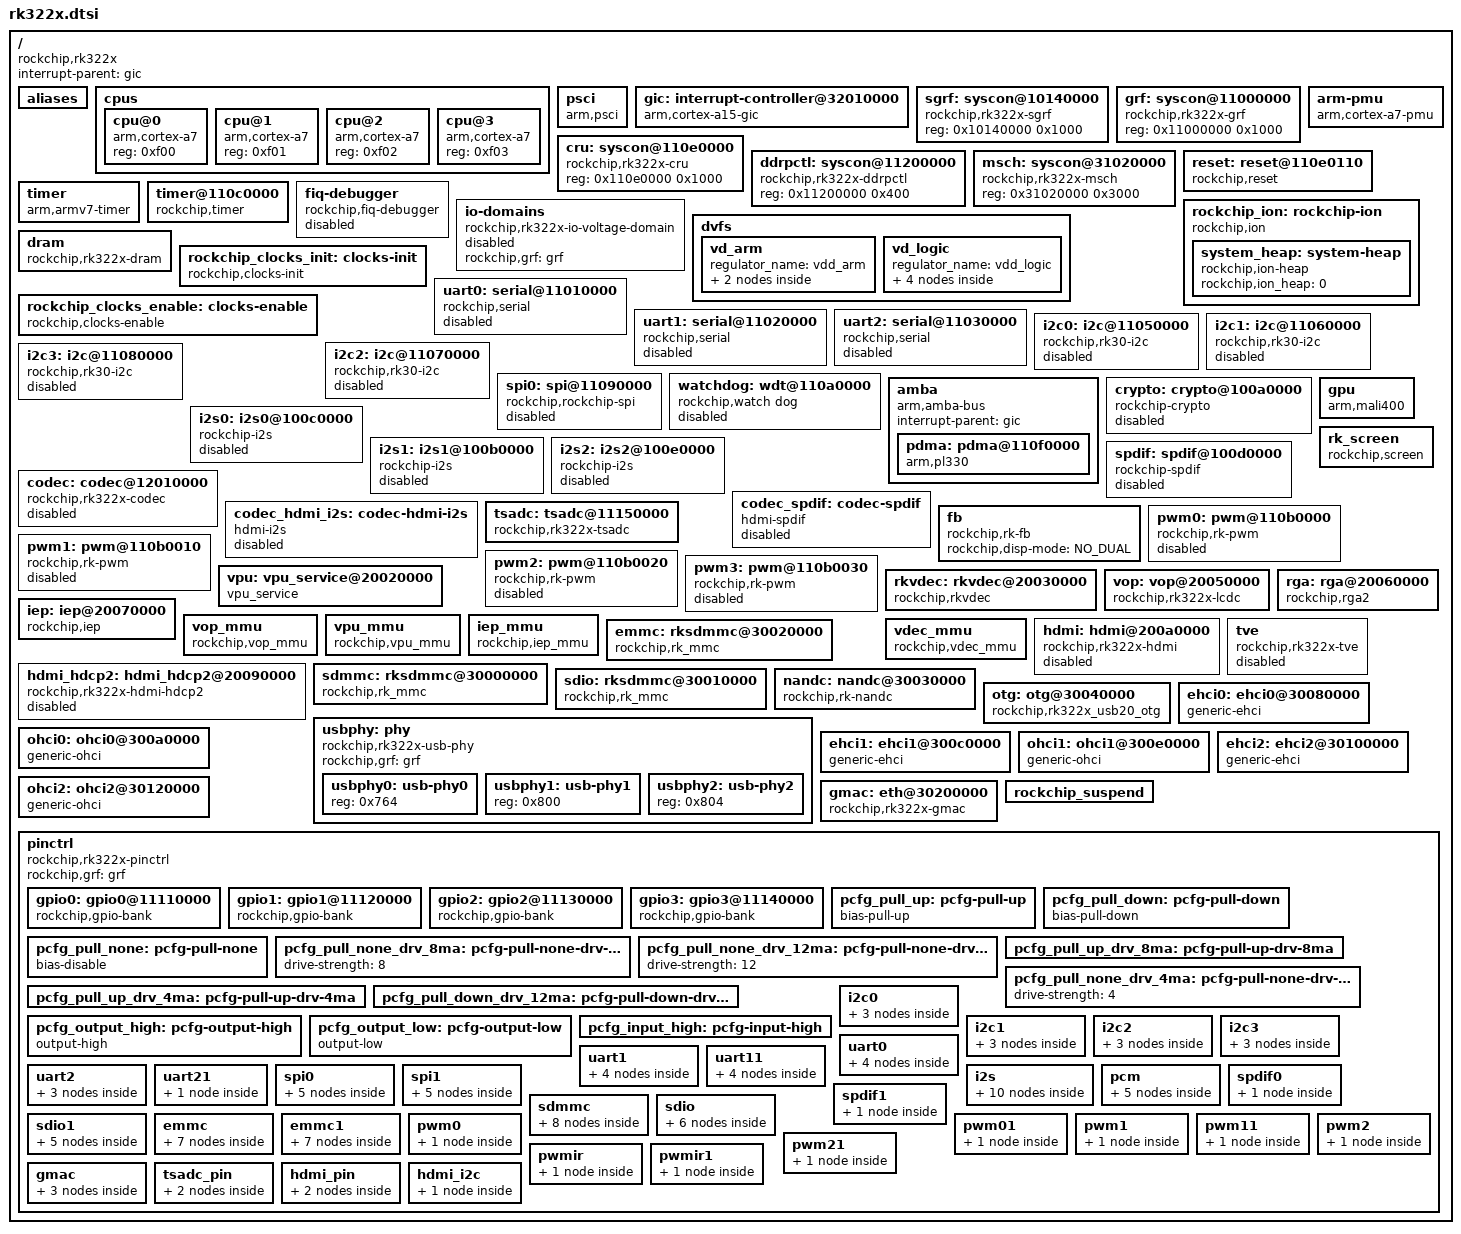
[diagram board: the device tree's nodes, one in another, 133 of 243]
#include <dt-bindings/interrupt-controller/arm-gic.h>
#include <dt-bindings/rkfb/rk_fb.h>

#include "skeleton.dtsi"
#include "rk322x-clocks.dtsi"

#include <dt-bindings/pinctrl/rockchip.h>
#include <dt-bindings/gpio/gpio.h>
#include <dt-bindings/clock/rk_system_status.h>
#include <rk322x_dram_default_timing.dtsi>
#include <dt-bindings/suspend/rockchip-pm.h>

/ {
	compatible = "rockchip,rk322x";
	interrupt-parent = <&gic>;

	aliases {
		serial0 = &uart0;
		serial1 = &uart1;
		serial2 = &uart2;
		i2c0 = &i2c0;
		i2c1 = &i2c1;
		i2c2 = &i2c2;
		i2c3 = &i2c3;
		lcdc0 = &vop;
		spi0 = &spi0;
	};

	cpus {
		#address-cells = <1>;
		#size-cells = <0>;

		cpu@0 {
			device_type = "cpu";
			compatible = "arm,cortex-a7";
			reg = <0xf00>;
		};
		cpu@1 {
			device_type = "cpu";
			compatible = "arm,cortex-a7";
			reg = <0xf01>;
		};
		cpu@2 {
			device_type = "cpu";
			compatible = "arm,cortex-a7";
			reg = <0xf02>;
		};
		cpu@3 {
			device_type = "cpu";
			compatible = "arm,cortex-a7";
			reg = <0xf03>;
		};
	};

	psci {
		compatible      = "arm,psci";
		method          = "smc";
		cpu_suspend     = <0x84000001>;
		cpu_off         = <0x84000002>;
		cpu_on          = <0x84000003>;
	};

	gic: interrupt-controller@32010000 {
		compatible = "arm,cortex-a15-gic";
		interrupt-controller;
		#interrupt-cells = <3>;
		#address-cells = <0>;
		reg = <0x32011000 0x1000>,
		      <0x32012000 0x1000>;
	};

	sgrf: syscon@10140000 {
		compatible = "rockchip,rk322x-sgrf", "rockchip,sgrf", "syscon";
		reg = <0x10140000 0x1000>;
	};

	grf: syscon@11000000 {
		compatible = "rockchip,rk322x-grf", "rockchip,grf", "syscon";
		reg = <0x11000000 0x1000>;
	};

	cru: syscon@110e0000 {
		compatible = "rockchip,rk322x-cru", "rockchip,cru", "syscon";
		reg = <0x110e0000 0x1000>;
	};

	ddrpctl: syscon@11200000 {
		compatible = "rockchip,rk322x-ddrpctl", "syscon";
		reg = <0x11200000 0x400>;
	};

	msch: syscon@31020000 {
		compatible = "rockchip,rk322x-msch", "rockchip,msch", "syscon";
		reg = <0x31020000 0x3000>;
	};

	arm-pmu {
		compatible = "arm,cortex-a7-pmu";
		interrupts = <GIC_SPI 76 IRQ_TYPE_LEVEL_HIGH>,
			     <GIC_SPI 77 IRQ_TYPE_LEVEL_HIGH>,
			     <GIC_SPI 78 IRQ_TYPE_LEVEL_HIGH>,
			     <GIC_SPI 79 IRQ_TYPE_LEVEL_HIGH>;
	};

	reset: reset@110e0110{
		compatible = "rockchip,reset";
		reg = <0x110e0110 0x20>;
		rockchip,reset-flag = <ROCKCHIP_RESET_HIWORD_MASK>;
		#reset-cells = <1>;
	};

	timer {
		compatible = "arm,armv7-timer";
		interrupts = <GIC_PPI 13
			      (GIC_CPU_MASK_SIMPLE(4) | IRQ_TYPE_LEVEL_HIGH)>,
			     <GIC_PPI 14
			      (GIC_CPU_MASK_SIMPLE(4) | IRQ_TYPE_LEVEL_HIGH)>;
		clock-frequency = <24000000>;
	};

	timer@110c0000 {
		compatible = "rockchip,timer";
		reg = <0x110c0000 0x20>;
		interrupts = <GIC_SPI 43 IRQ_TYPE_LEVEL_HIGH>;
		rockchip,broadcast = <1>;
	};

	fiq-debugger {
		compatible = "rockchip,fiq-debugger";
		rockchip,serial-id = <2>;
		rockchip,signal-irq = <159>;
		rockchip,wake-irq = <0>;
		rockchip,irq-mode-enable = <0>;  /* If enable uart uses irq instead of fiq */
		rockchip,baudrate = <1500000>;  /* Only 115200 and 1500000 */
		pinctrl-names = "default";
		pinctrl-0 = <&uart21_xfer>;
		status = "disabled";
	};

	io-domains {
		compatible = "rockchip,rk322x-io-voltage-domain";
		rockchip,grf = <&grf>;
		status = "disabled";
	};

	dvfs {
		vd_arm: vd_arm {
			regulator_name = "vdd_arm";
			pd_core {
				clk_core_dvfs_table: clk_core {
					operating-points = <
						/* KHz    uV */
						312000 1200000
						504000 1200000
						816000 1200000
						1008000 1200000
						>;
					temp-limit-enable = <1>;
					target-temp = <95>;
					min_temp_limit = <600000>;
					normal-temp-limit = <
					/*delta-temp    delta-freq*/
						3	96000
						6	144000
						9	192000
						15	384000
						>;
					performance-temp-limit = <
						/*temp    freq*/
						110     816000
						>;
					status = "okay";
					regu-mode-table = <
						/*freq     mode*/
						1008000    4
						0          3
					>;
					regu-mode-en = <0>;
					lkg_adjust_volt_en = <1>;
					channel = <0>;
					tsadc-ch = <0>;
					def_table_lkg = <4>;
					min_adjust_freq = <1008000>;
					lkg_adjust_volt_table = <
						/*lkg(mA)  volt(uV)*/
						10	   50000
						20	   100000
						60         150000
						>;
				};
			};
		};

		vd_logic: vd_logic {
			regulator_name = "vdd_logic";
			pd_ddr {
				clk_ddr_dvfs_table: clk_ddr {
					operating-points = <
						/* KHz    uV */
						200000 1200000
						300000 1200000
						400000 1200000
						>;
					lkg_adjust_volt_en = <1>;
					channel = <2>;
					def_table_lkg = <5>;
					min_adjust_freq = <300000>;
					lkg_adjust_volt_table = <
						/*lkg(mA)  volt(uV)*/
						7	   50000
						60         100000
						>;
					status = "disabled";
				};
			};

			pd_gpu {
				clk_gpu_dvfs_table: clk_gpu {
					operating-points = <
						/* KHz    uV */
						200000 1200000
						300000 1200000
						400000 1200000
						>;
					channel = <2>;
					status = "okay";
					regu-mode-table = <
						/*freq     mode*/
						200000     4
						0          3
					>;
					regu-mode-en = <0>;
				};
			};
		};
	};

	rockchip_ion: rockchip-ion {
		compatible = "rockchip,ion";
		#address-cells = <1>;
		#size-cells = <0>;

		system_heap: system-heap {
			compatible = "rockchip,ion-heap";
			rockchip,ion_heap = <0>;
		};
	};

	dram: dram {
		compatible = "rockchip,rk322x-dram";
		status = "okay";
		dram_freq = <786000000>;
		rockchip,dram_timing = <&dram_timing>;
	};

	rockchip_clocks_init: clocks-init{
		compatible = "rockchip,clocks-init";
		rockchip,clocks-init-parent =
			<&clk_i2s0_pll &clk_gpll>, <&clk_i2s1_pll &clk_gpll>,
			<&clk_i2s2_pll &clk_gpll>, <&clk_spdif_pll &clk_gpll>,
			<&clk_gpu &clk_cpll>, <&dclk_vop0 &hdmi_phy_clk>,
			<&aclk_bus &clk_gpll>, <&aclk_peri &clk_gpll>,
			<&clk_sdmmc0 &clk_cpll>, <&clk_emmc &clk_cpll>,
			<&clk_sdio &clk_cpll>, <&aclk_vpu &clk_cpll>,
			<&hdmi_phy_clk &hdmiphy_out>, <&usb480m &usb480m_phy>,
			<&aclk_rkvdec &clk_cpll>;
		rockchip,clocks-init-rate =
			<&clk_gpll 1200000000>, <&clk_core 700000000>,
			<&clk_cpll 500000000>, <&aclk_bus 150000000>,
			<&hclk_bus 150000000>, <&pclk_bus 75000000>,
			<&aclk_peri 150000000>, <&hclk_peri 150000000>,
			<&pclk_peri 75000000>, <&clk_mac 125000000>,
			<&aclk_iep 250000000>, <&hclk_vio 125000000>,
			<&aclk_rga 250000000>, <&clk_gpu 250000000>,
			<&aclk_vpu 25000000>, <&clk_vdec_core 250000000>,
			<&clk_vdec_cabac 250000000>, <&aclk_rkvdec 16000000>,
			<&aclk_vop 400000000>;
/*
		rockchip,clocks-uboot-has-init =
			<&aclk_vio0>;
*/
	};

	rockchip_clocks_enable: clocks-enable {
		compatible = "rockchip,clocks-enable";
		clocks =
			/*PLL*/
			<&clk_apll>,
			<&clk_dpll>,
			<&clk_gpll>,
			<&clk_cpll>,

			/*PD_CORE*/
			<&clk_core>,
			<&pclk_dbg>,
			<&aclk_core>,
			<&clk_gates4 2>,

			/*PD_BUS*/
			<&clk_gates6 3>,/*pclk_bus_pre*/
			<&clk_gates7 1>,/*clk4x_ddrphy*/
			<&clk_gates8 5>,/*clk_ddrupctl*/
			<&clk_gates8 0>,/*aclk_intmem*/
			<&clk_gates8 1>,/*clk_intmem_mbist*/
			<&clk_gates8 2>,/*aclk_dmac_bus*/
			<&clk_gates10 1>,/*g_aclk_bus*/
			<&clk_gates8 3>,/*hclk_rom*/
			<&clk_gates8 4>,/*pclk_ddrupctl*/
			<&clk_gates8 6>,/*pclk_ddrmon*/
			<&clk_gates9 4>,/*pclk_timer0*/
			<&clk_gates9 5>,/*pclk_stimer*/
			<&clk_gates9 8>,/*pclk_gpio0*/
			<&clk_gates10 0>,/*pclk_grf*/
			<&clk_gates10 4>,/*pclk_cru*/
			<&clk_gates10 6>,/*pclk_sgrf*/
			<&clk_gates10 3>,/*pclk_ddrphy*/
			<&clk_gates10 9>,/*pclk_phy_noc*/
			<&clk_gates10 2>,/*pclk_mschniu*/

			/*PD_PERI*/
			<&clk_gates12 0>,/*aclk_peri_noc*/
			<&clk_gates12 1>,/*hclk_peri_noc*/
			<&clk_gates12 2>,/*pclk_peri_noc*/

			/*PD_VIO*/
			<&clk_gates13 7>,/*hclk_vio_ahb_arbi*/
			<&clk_gates14 7>,/*hclk_vio_h2p*/

			<&clk_gates6 5>, /* g_clk_timer0 */
			<&clk_gates6 6>, /* g_clk_timer1 */

			/*PD_VIDEO*/
			<&clk_gates15 4>,/*g_aclk_vpu_noc*/
			<&clk_gates15 6>,/*g_aclk_rkvdec_noc*/
			<&clk_gates15 5>,/*g_hclk_vpu_noc*/
			<&clk_gates15 7>,/*g_hclk_rkvdec_noc*/

			<&clk_gates13 11>,/*g_aclk_rga_noc*/
			
			<&clk_gates7 15>, /* g_aclk_gpu_noc */

			<&clk_gates13 9>,/*g_aclk_iep_noc*/
			<&clk_gates13 12>,/*g_aclk_vop_noc*/
			<&clk_gates13 10>,/*g_aclk_hdcp_noc*/
			<&clk_gates13 8>,/*g_hclk_vio_noc*/
			<&clk_gates13 13>,/*g_hclk_vop_noc*/

			<&clk_gates1 3>;/*clk_jtag*/
	};

	uart0: serial@11010000 {
		compatible = "rockchip,serial";
		reg = <0x11010000 0x100>;
		interrupts = <GIC_SPI 55 IRQ_TYPE_LEVEL_HIGH>;
		clock-frequency = <24000000>;
		clocks = <&clk_uart0>, <&clk_gates9 12>;
		clock-names = "sclk_uart", "pclk_uart";
		reg-shift = <2>;
		reg-io-width = <4>;
		dmas = <&pdma 2>, <&pdma 3>;
		#dma-cells = <2>;
		pinctrl-names = "default";
		pinctrl-0 = <&uart0_xfer &uart0_cts &uart0_rts>;
		status = "disabled";
	};

	uart1: serial@11020000 {
		compatible = "rockchip,serial";
		reg = <0x11020000 0x100>;
		interrupts = <GIC_SPI 56 IRQ_TYPE_LEVEL_HIGH>;
		clock-frequency = <24000000>;
		clocks = <&clk_uart1>, <&clk_gates9 13>;
		clock-names = "sclk_uart", "pclk_uart";
		reg-shift = <2>;
		reg-io-width = <4>;
		dmas = <&pdma 4>, <&pdma 5>;
		#dma-cells = <2>;
		pinctrl-names = "default";
		pinctrl-0 = <&uart11_xfer &uart11_cts &uart11_rts>;
		status = "disabled";
	};

	uart2: serial@11030000 {
		compatible = "rockchip,serial";
		reg = <0x11030000 0x100>;
		interrupts = <GIC_SPI 57 IRQ_TYPE_LEVEL_HIGH>;
		clock-frequency = <24000000>;
		clocks = <&clk_uart2>, <&clk_gates9 14>;
		clock-names = "sclk_uart", "pclk_uart";
		reg-shift = <2>;
		reg-io-width = <4>;
		dmas = <&pdma 6>, <&pdma 7>;
		#dma-cells = <2>;
		pinctrl-names = "default";
		pinctrl-0 = <&uart21_xfer>;
		status = "disabled";
	};

	i2c0: i2c@11050000 {
		compatible = "rockchip,rk30-i2c";
		reg = <0x11050000 0x1000>;
		interrupts = <GIC_SPI 36 IRQ_TYPE_LEVEL_HIGH>;
		#address-cells = <1>;
		#size-cells = <0>;
		pinctrl-names = "default", "gpio", "sleep";
		pinctrl-0 = <&i2c0_xfer>;
		pinctrl-1 = <&i2c0_gpio>;
		pinctrl-2 = <&i2c0_sleep>;
		gpios = <&gpio0 GPIO_A1 GPIO_ACTIVE_LOW>,
			<&gpio0 GPIO_A0 GPIO_ACTIVE_LOW>;
		clocks = <&clk_gates8 15>;
		rockchip,check-idle = <1>;
		status = "disabled";
	};

	i2c1: i2c@11060000 {
		compatible = "rockchip,rk30-i2c";
		reg = <0x11060000 0x1000>;
		interrupts = <GIC_SPI 37 IRQ_TYPE_LEVEL_HIGH>;
		#address-cells = <1>;
		#size-cells = <0>;
		pinctrl-names = "default", "gpio", "sleep";
		pinctrl-0 = <&i2c1_xfer>;
		pinctrl-1 = <&i2c1_gpio>;
		pinctrl-2 = <&i2c1_sleep>;
		gpios = <&gpio0 GPIO_A3 GPIO_ACTIVE_LOW>,
			<&gpio0 GPIO_A2 GPIO_ACTIVE_LOW>;
		clocks = <&clk_gates9 0>;
		rockchip,check-idle = <1>;
		status = "disabled";
	};

	i2c2: i2c@11070000 {
		compatible = "rockchip,rk30-i2c";
		reg = <0x11070000 0x1000>;
		interrupts = <GIC_SPI 38 IRQ_TYPE_LEVEL_HIGH>;
		#address-cells = <1>;
		#size-cells = <0>;
		pinctrl-names = "default", "gpio", "sleep";
		pinctrl-0 = <&i2c2_xfer>;
		pinctrl-1 = <&i2c2_gpio>;
		pinctrl-2 = <&i2c2_sleep>;
		gpios = <&gpio2 GPIO_C4 GPIO_ACTIVE_LOW>,
			<&gpio2 GPIO_C5 GPIO_ACTIVE_LOW>;
		clocks = <&clk_gates9 1>;
		rockchip,check-idle = <1>;
		status = "disabled";
	};

	i2c3: i2c@11080000 {
		compatible = "rockchip,rk30-i2c";
		reg = <0x11080000 0x1000>;
		interrupts = <GIC_SPI 39 IRQ_TYPE_LEVEL_HIGH>;
		#address-cells = <1>;
		#size-cells = <0>;
		pinctrl-names = "default", "gpio", "sleep";
		pinctrl-0 = <&i2c3_xfer>;
		pinctrl-1 = <&i2c3_gpio>;
		pinctrl-2 = <&i2c3_sleep>;
		gpios = <&gpio0 GPIO_A7 GPIO_ACTIVE_LOW>,
			<&gpio0 GPIO_A6 GPIO_ACTIVE_LOW>;
		clocks = <&clk_gates9 2>;
		rockchip,check-idle = <1>;
		status = "disabled";
	};

	spi0: spi@11090000 {
		compatible = "rockchip,rockchip-spi";
		reg = <0x11090000 0x1000>;
		interrupts = <GIC_SPI 49 IRQ_TYPE_LEVEL_HIGH>;
		#address-cells = <1>;
		#size-cells = <0>;
		pinctrl-names = "default";
		pinctrl-0 = <&spi0_clk &spi0_tx &spi0_rx &spi0_cs0 &spi0_cs1>;
		rockchip,spi-src-clk = <0>;
		num-cs = <2>;
		clocks =<&clk_gates2 9>, <&clk_gates9 6>;
		clock-names = "spi", "pclk_spi0";
		//dmas = <&pdma 8>, <&pdma 9>;
		//#dma-cells = <2>;
		//dma-names = "!tx", "rx";
		status = "disabled";
	};

	watchdog: wdt@110a0000 {
		compatible = "rockchip,watch dog";
		reg = <0x110a0000 0x100>;
		clocks = <&clk_gates6 3>;  /* pclk_bus_pre */
		clock-names = "pclk_wdt";
		interrupts = <GIC_SPI 40 IRQ_TYPE_LEVEL_HIGH>;
		rockchip,irq = <1>;
		rockchip,timeout = <60>;
		rockchip,atboot = <1>;
		rockchip,debug = <0>;
		status = "disabled";
	};

	amba {
		#address-cells = <1>;
		#size-cells = <1>;
		compatible = "arm,amba-bus";
		interrupt-parent = <&gic>;
		ranges;

		pdma: pdma@110f0000 {
			compatible = "arm,pl330", "arm,primecell";
			reg = <0x110f0000 0x4000>;
			clocks = <&clk_gates8 2>;
			clock-names = "apb_pclk";
			interrupts = <GIC_SPI 0 IRQ_TYPE_LEVEL_HIGH>,
				     <GIC_SPI 1 IRQ_TYPE_LEVEL_HIGH>;
			#dma-cells = <1>;
		};
	};

	crypto: crypto@100a0000 {
		compatible = "rockchip-crypto";
		reg = <0x100a0000 0x10000>;
		interrupts = <GIC_SPI 30 IRQ_TYPE_LEVEL_HIGH>;
		interrupt-names = "irq_crypto";
		clocks = <&clk_crypto>, <&clk_gates8 12>, <&clk_gates8 11>;
		clock-names = "clk_crypto", "hclk_crypto", "aclk_crypto";
		status = "disabled";
	};

	i2s0: i2s0@100c0000 {
		compatible = "rockchip-i2s";
		reg = <0x100c0000 0x1000>;
		i2s-id = <0>;
		clocks = <&clk_i2s0>, <&clk_gates8 7>;
		clock-names = "i2s_clk", "i2s_hclk";
		interrupts = <GIC_SPI 26 IRQ_TYPE_LEVEL_HIGH>;
		dmas = <&pdma 11>, <&pdma 12>;
		#dma-cells = <2>;
		dma-names = "tx", "rx";
		status = "disabled";
	};

	i2s1: i2s1@100b0000 {
		compatible = "rockchip-i2s";
		reg = <0x100b0000 0x1000>;
		i2s-id = <1>;
		clocks = <&clk_i2s1>, <&clk_i2s1_out>, <&clk_gates8 8>;
		clock-names = "i2s_clk", "i2s_mclk", "i2s_hclk";
		interrupts = <GIC_SPI 27 IRQ_TYPE_LEVEL_HIGH>;
		dmas = <&pdma 14>, <&pdma 15>;
		#dma-cells = <2>;
		dma-names = "tx", "rx";
		status = "disabled";
	};

	i2s2: i2s2@100e0000 {
		compatible = "rockchip-i2s";
		reg = <0x100e0000 0x1000>;
		i2s-id = <2>;
		clocks = <&clk_i2s2>, <&clk_gates8 9>;
		clock-names = "i2s_clk", "i2s_hclk";
		interrupts = <GIC_SPI 28 IRQ_TYPE_LEVEL_HIGH>;
		dmas = <&pdma 0>, <&pdma 1>;
		#dma-cells = <2>;
		dma-names = "tx", "rx";
		pinctrl-names = "default", "sleep";
		pinctrl-0 = <&pcm_rx &pcm_tx &pcm_clk &pcm_sync>;
		pinctrl-1 = <&pcm_sleep>;
		status = "disabled";
	};

	spdif: spdif@100d0000 {
		compatible = "rockchip-spdif";
		reg = <0x100d0000 0x1000>;
		clocks = <&clk_spdif>, <&clk_gates8 10>;
		clock-names = "spdif_mclk", "spdif_hclk";
		interrupts = <GIC_SPI 29 IRQ_TYPE_LEVEL_HIGH>;
		dmas = <&pdma 10>;
		#dma-cells = <1>;
		dma-names = "tx";
		pinctrl-names = "default";
		pinctrl-0 = <&spdif1_tx>;
		status = "disabled";
	};

	codec: codec@12010000 {
		compatible = "rockchip,rk322x-codec";
		reg = <0x12010000 0x1000>;
		clocks = <&clk_gates10 5>;
		clock-names = "g_pclk_acodec";
		spk_ctl_io = <&gpio1 GPIO_A3 GPIO_ACTIVE_HIGH>;
		status = "disabled";
	};

	codec_spdif: codec-spdif {
		compatible = "hdmi-spdif";
		status = "disabled";
	};

	codec_hdmi_i2s: codec-hdmi-i2s {
		compatible = "hdmi-i2s";
		status = "disabled";
	};

	tsadc: tsadc@11150000 {
		compatible = "rockchip,rk322x-tsadc";
		reg = <0x11150000 0x100>;
		interrupts = <GIC_SPI 58 IRQ_TYPE_LEVEL_HIGH>;
		clock-frequency = <32768>;
		clocks = <&clk_tsadc>, <&clk_gates9 15>;
		clock-names = "tsadc", "pclk_tsadc";
		resets = <&reset RK322X_RST_TSADC>;
		reset-names = "tsadc-apb";
		#io-channel-cells = <1>;
		io-channel-ranges;
		pinctrl-names = "default";
		pinctrl-0 = <&tsadc_gpio>;
		tsadc-ht-temp = <120>;
		tsadc-ht-reset-cru = <1>;
		tsadc-ht-pull-gpio = <0>;
		status = "okay";
	};

	gpu {
		compatible = "arm,mali400";
		reg = <0x20001000 0x200>,
		      <0x20000000 0x100>,
		      <0x20003000 0x100>,
		      <0x20008000 0x1100>,
		      <0x20004000 0x100>,
		      <0x2000A000 0x1100>,
		      <0x20005000 0x100>;

		reg-names = "Mali_L2",
			    "Mali_GP",
			    "Mali_GP_MMU",
			    "Mali_PP0",
			    "Mali_PP0_MMU",
			    "Mali_PP1",
			    "Mali_PP1_MMU";

		interrupts = <GIC_SPI 6 IRQ_TYPE_LEVEL_HIGH>,
			     <GIC_SPI 5 IRQ_TYPE_LEVEL_HIGH>,
			     <GIC_SPI 4 IRQ_TYPE_LEVEL_HIGH>,
			     <GIC_SPI 5 IRQ_TYPE_LEVEL_HIGH>,
			     <GIC_SPI 4 IRQ_TYPE_LEVEL_HIGH>,
			     <GIC_SPI 5 IRQ_TYPE_LEVEL_HIGH>;

		interrupt-names = "Mali_GP_IRQ",
				  "Mali_GP_MMU_IRQ",
				  "Mali_PP0_IRQ",
				  "Mali_PP0_MMU_IRQ",
				  "Mali_PP1_IRQ",
				  "Mali_PP1_MMU_IRQ";
	};

	fb: fb {
		compatible = "rockchip,rk-fb";
		rockchip,disp-mode = <NO_DUAL>;
	};

	rk_screen: rk_screen {
		compatible = "rockchip,screen";
	};

	pwm0: pwm@110b0000 {
		compatible = "rockchip,rk-pwm";
		reg = <0x110b0000 0x10>;
		/* used by driver on remotectl'pwm */
		interrupts = <GIC_SPI 50 IRQ_TYPE_LEVEL_HIGH>;
		#pwm-cells = <2>;
		pinctrl-names = "default";
		pinctrl-0 = <&pwm01_pin>;
		clocks = <&clk_gates9 7>;
		clock-names = "pclk_pwm";
		status = "disabled";
	};

	pwm1: pwm@110b0010 {
		compatible = "rockchip,rk-pwm";
		reg = <0x110b0010 0x10>;
		/* used by driver on remotectl'pwm */
		interrupts = <GIC_SPI 50 IRQ_TYPE_LEVEL_HIGH>;
		#pwm-cells = <2>;
		pinctrl-names = "default";
		pinctrl-0 = <&pwm11_pin>;
		clocks = <&clk_gates9 7>;
		clock-names = "pclk_pwm";
		status = "disabled";
	};

	pwm2: pwm@110b0020 {
		compatible = "rockchip,rk-pwm";
		reg = <0x110b0020 0x10>;
		/* used by driver on remotectl'pwm */
		interrupts = <GIC_SPI 50 IRQ_TYPE_LEVEL_HIGH>;
		#pwm-cells = <2>;
		pinctrl-names = "default";
		pinctrl-0 = <&pwm21_pin>;
		clocks = <&clk_gates9 7>;
		clock-names = "pclk_pwm";
		status = "disabled";
	};

	pwm3: pwm@110b0030 {
		compatible = "rockchip,rk-pwm";
		reg = <0x110b0030 0x10>;
		/* used by driver on remotectl'pwm */
		interrupts = <GIC_SPI 50 IRQ_TYPE_LEVEL_HIGH>;
		#pwm-cells = <2>;
		pinctrl-names = "default";
		pinctrl-0 = <&pwmir1_pin>;
		clocks = <&clk_gates9 7>;
		clock-names = "pclk_pwm";
		status = "disabled";
	};

	vpu: vpu_service@20020000 {
		compatible = "vpu_service";
		rockchip,grf = <&grf>;
		iommu_enabled = <1>;
		reg = <0x20020000 0x800>;
		interrupts = <GIC_SPI  9 IRQ_TYPE_LEVEL_HIGH>,
			     <GIC_SPI 11 IRQ_TYPE_LEVEL_HIGH>;
		interrupt-names = "irq_dec", "irq_enc";
		clocks = <&aclk_vpu>, <&hclk_vpu>;
		clock-names = "aclk_vcodec", "hclk_vcodec";
		resets = <&reset RK322X_RST_VPU_H>, <&reset RK322X_RST_VPU_A>;
		reset-names = "video_h", "video_a";
		name = "vpu_service";
		dev_mode = <0>;
		status = "okay";
	};

	rkvdec: rkvdec@20030000 {
		compatible = "rockchip,rkvdec";
		rockchip,grf = <&grf>;
		iommu_enabled = <1>;
		reg = <0x20030000 0x400>;
		interrupts = <GIC_SPI 7 IRQ_TYPE_LEVEL_HIGH>;
		interrupt-names = "irq_dec";
		clocks = <&aclk_rkvdec>, <&hclk_rkvdec>, <&clk_vdec_cabac>, <&clk_vdec_core>;
		clock-names = "aclk_vcodec", "hclk_vcodec", "clk_cabac", "clk_core";
		resets = <&reset RK322X_RST_RKVDEC_H>, <&reset RK322X_RST_RKVDEC_A>;
		reset-names = "video_h", "video_a";
		dev_mode = <2>;
		name = "rkvdec";
		status = "okay";
	};

	vop: vop@20050000 {
		compatible = "rockchip,rk322x-lcdc";

		rockchip,prop = <PRMRY>;
		rockchip,cabc_mode = <0>;
		rockchip,pwr18 = <0>;
		rockchip,iommu-enabled = <1>;
		reg = <0x20050000 0x2000>;
		interrupts = <GIC_SPI 32 IRQ_TYPE_LEVEL_HIGH>;
		clocks = <&clk_gates13 5>,
			 <&dclk_vop0>,
			 <&clk_gates13 6>,
			 <&clk_gates13 12>,
			 <&clk_gates13 13>;
		clock-names = "aclk_vop",
			      "dclk_vop",
			      "hclk_vop",
			      "aclk_vop_noc",
			      "hclk_vop_noc";
	};

	rga: rga@20060000 {
		compatible = "rockchip,rga2";
		reg = <0x20060000 0x1000>;
		interrupts = <GIC_SPI 33 IRQ_TYPE_LEVEL_HIGH>;
		clocks = <&clk_gates13 0>, <&clk_gates13 1>, <&aclk_rga>;
		clock-names = "aclk_rga", "hclk_rga", "pd_rga";
	};

	iep: iep@20070000 {
		compatible = "rockchip,iep";
		iommu_enabled = <1>;
		reg = <0x20070000 0x800>;
		interrupts = <GIC_SPI 31 IRQ_TYPE_LEVEL_HIGH>;
		clocks = <&clk_gates13 2>, <&clk_gates13 3>;
		clock-names = "aclk_iep", "hclk_iep";
		version = <3>;
		status = "okay";
	};

	vop_mmu {
		dbgname = "vop";
		compatible = "rockchip,vop_mmu";
		reg = <0x20053f00 0x100>;
		interrupts = <GIC_SPI 32 IRQ_TYPE_LEVEL_HIGH>;
		interrupt-names = "vop_mmu";
	};

	vpu_mmu {
		dbgname = "vpu";
		compatible = "rockchip,vpu_mmu";
		reg = <0x20020800 0x100>;
		interrupts = <GIC_SPI 10 IRQ_TYPE_LEVEL_HIGH>;
		interrupt-names = "vpu_mmu";
	};

	iep_mmu {
		dbgname = "iep";
		compatible = "rockchip,iep_mmu";
		reg = <0x20070800 0x100>;
		interrupts = <GIC_SPI 31 IRQ_TYPE_LEVEL_HIGH>;
		interrupt-names = "iep_mmu";
	};

	vdec_mmu {
		dbgname = "vdec";
		compatible = "rockchip,vdec_mmu";
		reg = <0x20030480 0x40>,
		      <0x200304c0 0x40>;
		interrupts = <GIC_SPI 8 IRQ_TYPE_LEVEL_HIGH>;
		interrupt-names = "vdec_mmu";
	};

	hdmi: hdmi@200a0000 {
		compatible = "rockchip,rk322x-hdmi";
		reg = <0x200a0000 0x20000>,
		      <0x12030000 0x10000>;
		interrupts = <GIC_SPI 35 IRQ_TYPE_LEVEL_HIGH>,
			     <GIC_SPI 71 IRQ_TYPE_LEVEL_HIGH>;
		clocks = <&clk_gates3 7>,
			 <&clk_gates14 6>,
			 <&clk_gates10 7>,
			 <&clk_hdmi_cec>;
		clock-names = "hdcp_clk_hdmi",
			      "pclk_hdmi",
			      "pclk_hdmi_phy",
			      "cec_clk_hdmi";
		pinctrl-names = "default", "gpio";
		pinctrl-0 = <&hdmi_cec &hdmii2c_xfer &hdmi_hpd>;
		pinctrl-1 = <&i2c3_gpio>;
		resets = <&reset RK322X_RST_HDMI_P>;
		reset-names = "hdmi";
		rockchip,grf = <&grf>;
		rockchip,hdmi_audio_source = <0>;
		rockchip,hdcp_enable = <0>;
		rockchip,cec_enable = <0>;
		status = "disabled";
	};

	hdmi_hdcp2: hdmi_hdcp2@20090000 {
		compatible = "rockchip,rk322x-hdmi-hdcp2";
		reg = <0x20090000 0x10000>;
		interrupts = <GIC_SPI 34 IRQ_TYPE_LEVEL_HIGH>;
		clocks = <&clk_gates13 10>,
			 <&clk_gates14 12>,
			 <&clk_gates14 11>,
			 <&clk_gates14 10>,
			 <&clk_hdcp>;
		clock-names = "aclk_noc_hdcp2",
			      "hclk_hdcp2_mmu",
			      "pclk_hdcp2",
			      "aclk_hdcp2",
			      "hdcp2_clk_hdmi";
		status = "disabled";
	};

	tve: tve {
		compatible = "rockchip,rk322x-tve";
		reg = <0x20053e00 0x100>,
		      <0x12020000 0x10000>;
		clocks = <&clk_gates10 8>;
		clock-names = "pclk_vdac";
		saturation = <0x00305b46>;
		brightcontrast = <0x00009900>;
		adjtiming = <0xd6c00880>;
		lumafilter0 = <0x02ff0001>;
		lumafilter1 = <0xf40200fe>;
		lumafilter2 = <0xf332d910>;
		daclevel = <0x15>;
		status = "disabled";
	};

	emmc: rksdmmc@30020000 {
		compatible = "rockchip,rk_mmc", "rockchip,rk322x-sdmmc";
		reg = <0x30020000 0x10000>;
		interrupts = <GIC_SPI 14 IRQ_TYPE_LEVEL_HIGH>;
		#address-cells = <1>;
		#size-cells = <0>;
		clocks = <&clk_emmc>, <&clk_gates11 2>;
		clock-names = "clk_mmc", "hclk_mmc";
		num-slots = <1>;
		fifo-depth = <0x100>;
		bus-width = <8>;
		tune_regsbase = <0x1d8>;
		resets = <&reset RK322X_RST_EMMC>;
		reset-names = "mmc_ahb_reset";
	};

	sdmmc: rksdmmc@30000000 {
		compatible = "rockchip,rk_mmc", "rockchip,rk322x-sdmmc";
		reg = <0x30000000 0x10000>;
		interrupts = <GIC_SPI 12 IRQ_TYPE_LEVEL_HIGH>;
		#address-cells = <1>;
		#size-cells = <0>;
		pinctrl-names = "default", "idle";
		pinctrl-0 = <&sdmmc_clk &sdmmc_cmd &sdmmc_dectn &sdmmc_bus4 &sdmmc_pwren>;
		pinctrl-1 = <&sdmmc_gpio>;
		cd-gpios = <&gpio1 GPIO_C1 GPIO_ACTIVE_HIGH>; /* CD GPIO */
		clocks = <&clk_sdmmc0>, <&clk_gates11 0>;
		clock-names = "clk_mmc", "hclk_mmc";
		num-slots = <1>;
		fifo-depth = <0x100>;
		bus-width = <4>;
		resets = <&reset RK322X_RST_SDMMC0>;
		reset-names = "mmc_ahb_reset";
	};

	sdio: rksdmmc@30010000 {
		compatible = "rockchip,rk_mmc", "rockchip,rk322x-sdmmc";
		reg = <0x30010000 0x10000>;
		interrupts = <GIC_SPI 13 IRQ_TYPE_LEVEL_HIGH>;
		#address-cells = <1>;
		#size-cells = <0>;
		pinctrl-names = "default", "idle";
		pinctrl-0 = <&sdio1_cmd &sdio1_clk &sdio1_bus4>;
		pinctrl-1 = <&sdio1_gpio>;
		clocks = <&clk_sdio>, <&clk_gates11 1>;
		clock-names = "clk_mmc", "hclk_mmc";
		num-slots = <1>;
		fifo-depth = <0x100>;
		bus-width = <4>;
		tune_regsbase = <0x1c8>;
		resets = <&reset RK322X_RST_SDIO>;
		reset-names = "mmc_ahb_reset";
	};

	nandc: nandc@30030000 {
		compatible = "rockchip,rk-nandc";
		reg = <0x30030000 0x4000>;
		interrupts = <GIC_SPI 15 IRQ_TYPE_LEVEL_HIGH>;
		nandc_id = <0>;
		clocks = <&clk_nandc>, <&clk_gates1 0>, <&clk_gates11 3>;
		clock-names = "clk_nandc", "g_clk_nandc", "hclk_nandc";
	};

	usbphy: phy {
		compatible = "rockchip,rk322x-usb-phy";
		rockchip,grf = <&grf>;
		#address-cells = <1>;
		#size-cells = <0>;

		usbphy0: usb-phy0 {
			#phy-cells = <0>;
			reg = <0x764>;
		};

		usbphy1: usb-phy1 {
			#phy-cells = <0>;
			reg = <0x800>;
		};

		usbphy2: usb-phy2 {
			#phy-cells = <0>;
			reg = <0x804>;
		};
	};

	otg: otg@30040000 {
		compatible = "rockchip,rk322x_usb20_otg";
		reg = <0x30040000 0x40000>;
		interrupts = <GIC_SPI 23 IRQ_TYPE_LEVEL_HIGH>;
		clocks = <&clk_gates1 5>, <&clk_gates11 12>, <&clk_gates11 13>;
		clock-names = "clk_usbphy0", "hclk_otg", "hclk_otg_pmu";
		resets = <&reset RK322X_RST_USBOTG0>, <&reset RK322X_RST_UTMI0>,
				<&reset RK322X_RST_OTGC0>;
		reset-names = "otg_ahb", "otg_phy", "otg_controller";
		/*0 - Normal, 1 - Force Host, 2 - Force Device*/
		rockchip,usb-mode = <0>;
	};

	ehci0: ehci0@30080000 {
		compatible = "generic-ehci";
		reg = <0x30080000 0x20000>;
		interrupts = <GIC_SPI 16 IRQ_TYPE_LEVEL_HIGH>;
		clocks = <&clk_gates1 5>, <&clk_gates11 6>, <&clk_gates11 7>;
		clock-names = "clk_usbphy0", "hclk_host0", "hclk_host0_arb";
		phys = <&usbphy0>;
		phy-names = "usb";
		resets = <&reset RK322X_RST_USBHOST0>, <&reset RK322X_RST_UTMI1>,
				<&reset RK322X_RST_HOST_CTRL0>;
		reset-names = "host_ahb", "host_phy", "host_controller";
	};

	ohci0: ohci0@300a0000 {
		compatible = "generic-ohci";
		reg = <0x300a0000 0x20000>;
		interrupts = <GIC_SPI 17 IRQ_TYPE_LEVEL_HIGH>;
	};

	ehci1: ehci1@300c0000 {
		compatible = "generic-ehci";
		reg = <0x300c0000 0x20000>;
		interrupts = <GIC_SPI 19 IRQ_TYPE_LEVEL_HIGH>;
		clocks = <&clk_gates1 6>, <&clk_gates11 8>, <&clk_gates11 9>;
		clock-names = "clk_usbphy1", "hclk_host1", "hclk_host1_arb";
		phys = <&usbphy1>;
		phy-names = "usb";
		resets = <&reset RK322X_RST_USBHOST1>, <&reset RK322X_RST_UTMI2>,
				<&reset RK322X_RST_HOST_CTRL1>;
		reset-names = "host_ahb", "host_phy", "host_controller";
	};

	ohci1: ohci1@300e0000 {
		compatible = "generic-ohci";
		reg = <0x300e0000 0x20000>;
		interrupts = <GIC_SPI 20 IRQ_TYPE_LEVEL_HIGH>;
	};

	ehci2: ehci2@30100000 {
		compatible = "generic-ehci";
		reg = <0x30100000 0x20000>;
		interrupts = <GIC_SPI 66 IRQ_TYPE_LEVEL_HIGH>;
		clocks = <&clk_gates1 6>, <&clk_gates11 10>, <&clk_gates11 14>;
		clock-names = "clk_usbphy1", "hclk_host2", "hck_host2_arb";
		phys = <&usbphy2>;
		phy-names = "usb";
		resets = <&reset RK322X_RST_USBHOST2>, <&reset RK322X_RST_UTMI3>,
				<&reset RK322X_RST_HOST_CTRL2>;
		reset-names = "host_ahb", "host_phy", "host_controller";
	};

	ohci2: ohci2@30120000 {
		compatible = "generic-ohci";
		reg = <0x30120000 0x20000>;
		interrupts = <GIC_SPI 67 IRQ_TYPE_LEVEL_HIGH>;
	};

	gmac: eth@30200000 {
		compatible = "rockchip,rk322x-gmac";
		reg = <0x30200000 0x10000>;
		rockchip,cru = <&cru>;
		rockchip,grf = <&grf>;
		interrupts = <GIC_SPI 24 IRQ_TYPE_LEVEL_HIGH>;
		interrupt-names = "macirq";
		clocks = <&clk_mac>, <&clk_gates5 5>,
			<&clk_gates5 6>, <&clk_gates5 3>,
			<&clk_gates5 4>, <&clk_gates11 4>,
			<&clk_gates11 5>;
		clock-names = "clk_mac", "mac_clk_rx",
			"mac_clk_tx", "clk_mac_ref",
			"clk_mac_refout", "aclk_mac",
			"pclk_mac";
		phy-mode = "rgmii";
		pinctrl-names = "default";
		pinctrl-0 = <&rgmii_pins>;
		status = "okay";
	};

	rockchip_suspend: rockchip_suspend {

		rockchip,ctrbits = <
			(0
			 |RKPM_CTR_GTCLKS
			 |RKPM_CTR_PLLS
			 |RKPM_CTR_IDLESRAM_MD
			)
			>;
	};

	pinctrl: pinctrl {
		compatible = "rockchip,rk322x-pinctrl";
		rockchip,grf = <&grf>;
		#address-cells = <1>;
		#size-cells = <1>;
		ranges;

		gpio0: gpio0@11110000 {
			compatible = "rockchip,gpio-bank";
			reg =	<0x11110000 0x100>;
			interrupts = <GIC_SPI 51 IRQ_TYPE_LEVEL_HIGH>;
			clocks = <&clk_gates9 9>;

			gpio-controller;
			#gpio-cells = <2>;

			interrupt-controller;
			#interrupt-cells = <2>;
		};

		gpio1: gpio1@11120000 {
			compatible = "rockchip,gpio-bank";
			reg = <0x11120000 0x100>;
			interrupts = <GIC_SPI 52 IRQ_TYPE_LEVEL_HIGH>;
			clocks = <&clk_gates9 9>;

			gpio-controller;
			#gpio-cells = <2>;

			interrupt-controller;
			#interrupt-cells = <2>;
		};

		gpio2: gpio2@11130000 {
			compatible = "rockchip,gpio-bank";
			reg = <0x11130000 0x100>;
			interrupts = <GIC_SPI 53 IRQ_TYPE_LEVEL_HIGH>;
			clocks = <&clk_gates9 10>;

			gpio-controller;
			#gpio-cells = <2>;

			interrupt-controller;
			#interrupt-cells = <2>;
		};

		gpio3: gpio3@11140000 {
			compatible = "rockchip,gpio-bank";
			reg = <0x11140000 0x100>;
			interrupts = <GIC_SPI 54 IRQ_TYPE_LEVEL_HIGH>;
			clocks = <&clk_gates9 11>;

			gpio-controller;
			#gpio-cells = <2>;

			interrupt-controller;
			#interrupt-cells = <2>;
		};

		pcfg_pull_up: pcfg-pull-up {
			bias-pull-up;
		};

		pcfg_pull_down: pcfg-pull-down {
			bias-pull-down;
		};

		pcfg_pull_none: pcfg-pull-none {
			bias-disable;
		};

		pcfg_pull_none_drv_8ma: pcfg-pull-none-drv-8ma {
			drive-strength = <8>;
		};

		pcfg_pull_none_drv_12ma: pcfg-pull-none-drv-12ma {
			drive-strength = <12>;
		};

		pcfg_pull_up_drv_8ma: pcfg-pull-up-drv-8ma {
			bias-pull-up;
			drive-strength = <8>;
		};

		pcfg_pull_none_drv_4ma: pcfg-pull-none-drv-4ma {
			drive-strength = <4>;
		};

		pcfg_pull_up_drv_4ma: pcfg-pull-up-drv-4ma {
			bias-pull-up;
			drive-strength = <4>;
		};

		pcfg_pull_down_drv_12ma: pcfg-pull-down-drv-12ma {
                        bias-pull-down;
                        drive-strength = <12>;
                };

		pcfg_output_high: pcfg-output-high {
			output-high;
		};

		pcfg_output_low: pcfg-output-low {
			output-low;
		};

		pcfg_input_high: pcfg-input-high {
			bias-pull-up;
			input-enable;
		};

		i2c0 {
			i2c0_xfer: i2c0-xfer {
				rockchip,pins = <0 GPIO_A0 RK_FUNC_1 &pcfg_pull_none>,
						<0 GPIO_A1 RK_FUNC_1 &pcfg_pull_none>;
			};
			i2c0_gpio: i2c0-gpio {
				rockchip,pins = <0 GPIO_A0 RK_FUNC_GPIO &pcfg_pull_none>,
						<0 GPIO_A1 RK_FUNC_GPIO &pcfg_pull_none>;
			};
			i2c0_sleep: i2c0-sleep {
				rockchip,pins = <0 GPIO_A0 RK_FUNC_GPIO &pcfg_input_high>,
						<0 GPIO_A1 RK_FUNC_GPIO &pcfg_input_high>;
			};
		};

		i2c1 {
			i2c1_xfer: i2c1-xfer {
				rockchip,pins = <0 GPIO_A2 RK_FUNC_1 &pcfg_pull_none>,
						<0 GPIO_A3 RK_FUNC_1 &pcfg_pull_none>;
			};
			i2c1_gpio: i2c1-gpio {
				rockchip,pins = <0 GPIO_A2  RK_FUNC_GPIO &pcfg_pull_none>,
						<0 GPIO_A3 RK_FUNC_GPIO &pcfg_pull_none>;
			};
			i2c1_sleep: i2c1-sleep {
				rockchip,pins = <0 GPIO_A2 RK_FUNC_GPIO &pcfg_input_high>,
						<0 GPIO_A3 RK_FUNC_GPIO &pcfg_input_high>;

			};
		};

		i2c2 {
			i2c2_xfer: i2c2-xfer {
				rockchip,pins = <2 GPIO_C5 RK_FUNC_1 &pcfg_pull_none>,
						<2 GPIO_C4 RK_FUNC_1 &pcfg_pull_none>;
			};
			i2c2_gpio: i2c2-gpio {
				rockchip,pins = <2 GPIO_C5 RK_FUNC_GPIO &pcfg_pull_none>,
						<2 GPIO_C4 RK_FUNC_GPIO &pcfg_pull_none>;
                        };
			i2c2_sleep: i2c2-sleep {
				rockchip,pins = <2 GPIO_C5 RK_FUNC_GPIO &pcfg_input_high>,
						<2 GPIO_C4 RK_FUNC_GPIO &pcfg_input_high>;
                        };
		};

		i2c3 {
			i2c3_xfer: i2c3-xfer {
				rockchip,pins = <0 GPIO_A6 RK_FUNC_1 &pcfg_pull_none>,
						<0 GPIO_A7 RK_FUNC_1 &pcfg_pull_none>;
			};
			i2c3_gpio: i2c3-gpio {
				rockchip,pins = <0 GPIO_A6 RK_FUNC_GPIO &pcfg_pull_none>,
						<0 GPIO_A7 RK_FUNC_GPIO &pcfg_pull_none>;
			};
			i2c3_sleep: i2c3-sleep {
				rockchip,pins = <0 GPIO_A6 RK_FUNC_GPIO &pcfg_input_high>,
						<0 GPIO_A7 RK_FUNC_GPIO &pcfg_input_high>;
			};
		};

		uart0 {
			uart0_xfer: uart0-xfer {
				rockchip,pins = <2 GPIO_D2 RK_FUNC_1 &pcfg_pull_up>,
						<2 GPIO_D3 RK_FUNC_1 &pcfg_pull_none>;
			};

			uart0_cts: uart0-cts {
				rockchip,pins = <2 GPIO_D5 RK_FUNC_1 &pcfg_pull_none>;
			};

			uart0_rts: uart0-rts {
				rockchip,pins = <0 GPIO_C1 RK_FUNC_1 &pcfg_pull_none>;
			};

			uart0_rts_gpio: uart0-rts-gpio {
				rockchip,pins = <0 GPIO_C1 RK_FUNC_GPIO &pcfg_pull_none>;
			};
		};

		uart1 {
			uart1_xfer: uart1-xfer {
				rockchip,pins = <1 GPIO_B2 RK_FUNC_1 &pcfg_pull_up>,
						<1 GPIO_B1 RK_FUNC_1 &pcfg_pull_none>;
			};

			uart1_cts: uart1-cts {
				rockchip,pins = <1 GPIO_B0 RK_FUNC_1 &pcfg_pull_none>;
			};

			uart1_rts: uart1-rts {
				rockchip,pins = <1 GPIO_B3 RK_FUNC_1 &pcfg_pull_none>;
			};

			uart1_rts_gpio: uart1-rts-gpio {
				rockchip,pins = <1 GPIO_B3 RK_FUNC_GPIO &pcfg_pull_none>;
			};
		};

		uart11 {
			uart11_xfer: uart11-xfer {
				rockchip,pins = <3 GPIO_B6 RK_FUNC_1 &pcfg_pull_up>,
						<3 GPIO_B5 RK_FUNC_1 &pcfg_pull_none>;
			};

			uart11_cts: uart11-cts {
				rockchip,pins = <3 GPIO_A7 RK_FUNC_1 &pcfg_pull_none>;
			};

			uart11_rts: uart11-rts {
				rockchip,pins = <3 GPIO_A6 RK_FUNC_1 &pcfg_pull_none>;
			};

			uart11_rts_gpio: uart11-rts-gpio {
				rockchip,pins = <3 GPIO_A6 RK_FUNC_GPIO &pcfg_pull_none>;
			};
		};

		uart2 {
			uart2_xfer: uart2-xfer {
				rockchip,pins = <1 GPIO_C2 RK_FUNC_2 &pcfg_pull_up>,
						<1 GPIO_C3 RK_FUNC_2 &pcfg_pull_none>;
			};

			uart2_cts: uart2-cts {
				rockchip,pins = <0 GPIO_D1 RK_FUNC_1 &pcfg_pull_none>;
			};

			uart2_rts: uart2-rts {
				rockchip,pins = <0 GPIO_D0 RK_FUNC_1 &pcfg_pull_none>;
			};
		};

		uart21 {
			uart21_xfer: uart21-xfer {
				rockchip,pins = <1 GPIO_B2 RK_FUNC_2 &pcfg_pull_up>,
						<1 GPIO_B1 RK_FUNC_2 &pcfg_pull_none>;
			};
		};

		spi0 {
			spi0_clk: spi0-clk {
				rockchip,pins = <0 GPIO_B1 RK_FUNC_2 &pcfg_pull_up>;
			};
			spi0_cs0: spi0-cs0 {
				rockchip,pins = <0 GPIO_B6 RK_FUNC_2 &pcfg_pull_up>;
			};
			spi0_tx: spi0-tx {
				rockchip,pins = <0 GPIO_B3 RK_FUNC_2 &pcfg_pull_up>;
			};
			spi0_rx: spi0-rx {
				rockchip,pins = <0 GPIO_B5 RK_FUNC_2 &pcfg_pull_up>;
			};
			spi0_cs1: spi0-cs1 {
				rockchip,pins = <1 GPIO_B4 RK_FUNC_1 &pcfg_pull_up>;
			};
		};

		spi1 {
			spi1_clk: spi1-clk {
				rockchip,pins = <0 GPIO_C7 RK_FUNC_2 &pcfg_pull_up>;
			};
			spi1_cs0: spi1-cs0 {
				rockchip,pins = <2 GPIO_A2 RK_FUNC_2 &pcfg_pull_up>;
			};
			spi1_rx: spi1-rx {
				rockchip,pins = <2 GPIO_A0 RK_FUNC_2 &pcfg_pull_up>;
			};
			spi1_tx: spi1-tx {
				rockchip,pins = <2 GPIO_A1 RK_FUNC_2 &pcfg_pull_up>;
			};
			spi1_cs1: spi1-cs1 {
				rockchip,pins = <2 GPIO_A3 RK_FUNC_2 &pcfg_pull_up>;
			};
		};

		i2s {
			i2s_mclk: i2s-mclk {
				rockchip,pins =	<0 GPIO_B0 RK_FUNC_1 &pcfg_pull_none>;
			};

			i2s_sclk:i2s-sclk {
				rockchip,pins =	<0 GPIO_B1 RK_FUNC_1 &pcfg_pull_none>;
			};

			i2s_lrckrx:i2s-lrckrx {
				rockchip,pins =	<0 GPIO_B3 RK_FUNC_1 &pcfg_pull_none>;
			};

			i2s_lrcktx:i2s-lrcktx {
				rockchip,pins =	<0 GPIO_B4 RK_FUNC_1 &pcfg_pull_none>;
			};

			i2s_sdi:i2s-sdi {
				rockchip,pins =	<0 GPIO_B6 RK_FUNC_1 &pcfg_pull_none>;
			};

			i2s_sdo0:i2s-sdo0 {
				rockchip,pins =	<0 GPIO_B5 RK_FUNC_1 &pcfg_pull_none>;
			};

			i2s_sdo1:i2s-sdo1 {
				rockchip,pins =	<1 GPIO_A2 RK_FUNC_2 &pcfg_pull_none>;
			};

			i2s_sdo2:i2s-sdo2 {
				rockchip,pins =	<1 GPIO_A4 RK_FUNC_2 &pcfg_pull_none>;
			};

			i2s_sdo3:i2s-sdo3 {
				rockchip,pins =	<1 GPIO_A5 RK_FUNC_2 &pcfg_pull_none>;
			};

			i2s_sleep: i2s-sleep {
				rockchip,pins = <0 GPIO_B0  RK_FUNC_GPIO &pcfg_input_high>,
						<0 GPIO_B1 RK_FUNC_GPIO &pcfg_input_high>,
						<0 GPIO_B3 RK_FUNC_GPIO &pcfg_input_high>,
						<0 GPIO_B4 RK_FUNC_GPIO &pcfg_input_high>,
						<0 GPIO_B6 RK_FUNC_GPIO &pcfg_input_high>,
						<0 GPIO_B5 RK_FUNC_GPIO &pcfg_input_high>,
						<1 GPIO_A2 RK_FUNC_GPIO &pcfg_input_high>,
						<1 GPIO_A4 RK_FUNC_GPIO &pcfg_input_high>,
						<1 GPIO_A5 RK_FUNC_GPIO &pcfg_input_high>;
			};
		};

		pcm {
			pcm_rx: pcm-rx {
				rockchip,pins = <0 GPIO_D2 RK_FUNC_2 &pcfg_pull_none>;
			};

			pcm_tx: pcm-tx {
				rockchip,pins = <0 GPIO_D3 RK_FUNC_2 &pcfg_pull_none>;
			};

			pcm_clk: pcm-clk {
				rockchip,pins = <3 GPIO_B3 RK_FUNC_1 &pcfg_pull_none>;
			};

			pcm_sync: pcm-sync {
				rockchip,pins = <3 GPIO_B4 RK_FUNC_1 &pcfg_pull_none>;
			};

			pcm_sleep: pcm-sleep {
				rockchip,pins = <0 GPIO_D2 RK_FUNC_GPIO &pcfg_input_high>,
						<0 GPIO_D3 RK_FUNC_GPIO &pcfg_input_high>,
						<3 GPIO_B3 RK_FUNC_GPIO &pcfg_input_high>,
						<3 GPIO_B4 RK_FUNC_GPIO &pcfg_input_high>;
			};
		};

		spdif0 {
			spdif0_tx: spdif0-tx {
				rockchip,pins =	<3 GPIO_D3 RK_FUNC_1 &pcfg_pull_none>;
			};
		};

		spdif1 {
			spdif1_tx: spdif1-tx {
				rockchip,pins =	<3 GPIO_D7 RK_FUNC_2 &pcfg_pull_none>;
			};
		};

		sdmmc {
			sdmmc_clk: sdmmc-clk {
				rockchip,pins = <1 GPIO_C0 RK_FUNC_1 &pcfg_pull_none_drv_4ma>;
			};

			sdmmc_cmd: sdmmc-cmd {
				rockchip,pins = <1 GPIO_B7 RK_FUNC_1 &pcfg_pull_up_drv_4ma>;
			};

			sdmmc_dectn: sdmmc-dectn {
				rockchip,pins = <1 GPIO_C1 RK_FUNC_1 &pcfg_pull_up_drv_4ma>;
			};

			sdmmc_wrprt: sdmmc-wrprt {
				rockchip,pins = <1 GPIO_A7 RK_FUNC_1 &pcfg_pull_up_drv_4ma>;
			};

			sdmmc_pwren: sdmmc-pwren {
				rockchip,pins = <1 GPIO_B6 RK_FUNC_1 &pcfg_pull_up_drv_4ma>;
			};

			sdmmc_bus1: sdmmc-bus1 {
				rockchip,pins = <1 GPIO_C2 RK_FUNC_1 &pcfg_pull_up_drv_4ma>;
			};

			sdmmc_bus4: sdmmc-bus4 {
				rockchip,pins = <1 GPIO_C2 RK_FUNC_1 &pcfg_pull_up_drv_4ma>,
						<1 GPIO_C3 RK_FUNC_1 &pcfg_pull_up_drv_4ma>,
						<1 GPIO_C4 RK_FUNC_1 &pcfg_pull_up_drv_4ma>,
						<1 GPIO_C5 RK_FUNC_1 &pcfg_pull_up_drv_4ma>;
			};

			sdmmc_gpio: sdmmc-gpio {
				rockchip,pins = <1 GPIO_C0 RK_FUNC_GPIO &pcfg_pull_up_drv_4ma>,
						<1 GPIO_B7 RK_FUNC_GPIO &pcfg_pull_up_drv_4ma>,
						<1 GPIO_C1 RK_FUNC_GPIO &pcfg_pull_up_drv_4ma>,
						<1 GPIO_A7 RK_FUNC_GPIO &pcfg_pull_up_drv_4ma>,
						<1 GPIO_B6 RK_FUNC_GPIO &pcfg_pull_up_drv_4ma>,
						<1 GPIO_C2 RK_FUNC_GPIO &pcfg_pull_up_drv_4ma>,
						<1 GPIO_C3 RK_FUNC_GPIO &pcfg_pull_up_drv_4ma>,
						<1 GPIO_C4 RK_FUNC_GPIO &pcfg_pull_up_drv_4ma>,
						<1 GPIO_C5 RK_FUNC_GPIO &pcfg_pull_up_drv_4ma>;
			};
		};

		sdio {
			sdio_bus1: sdio-bus1 {
				rockchip,pins = <1 GPIO_A1 RK_FUNC_1 &pcfg_pull_up_drv_4ma>;
			};

			sdio_bus4: sdio-bus4 {
				rockchip,pins = <1 GPIO_A1 RK_FUNC_1 &pcfg_pull_up_drv_4ma>,
						<1 GPIO_A2 RK_FUNC_1 &pcfg_pull_up_drv_4ma>,
						<1 GPIO_A4 RK_FUNC_1 &pcfg_pull_up_drv_4ma>,
						<1 GPIO_A5 RK_FUNC_1 &pcfg_pull_up_drv_4ma>;
			};

			sdio_cmd: sdio-cmd {
				rockchip,pins = <0 GPIO_A3 RK_FUNC_2 &pcfg_pull_up_drv_4ma>;
			};

			sdio_clk: sdio-clk {
				rockchip,pins = <1 GPIO_A0 RK_FUNC_1 &pcfg_pull_none_drv_4ma>;
			};

			sdio_pwren: sdio-pwren {
				rockchip,pins = <0 GPIO_D6 RK_FUNC_1 &pcfg_pull_up>;
			};

			sdio_gpio: sdio-gpio {
				rockchip,pins = <0 GPIO_A3 RK_FUNC_GPIO &pcfg_pull_up_drv_4ma>,
						<1 GPIO_A0 RK_FUNC_GPIO &pcfg_pull_up_drv_4ma>,
						<0 GPIO_D6 RK_FUNC_GPIO &pcfg_pull_up_drv_4ma>,
						<1 GPIO_A1 RK_FUNC_GPIO &pcfg_pull_up_drv_4ma>,
						<1 GPIO_A2 RK_FUNC_GPIO &pcfg_pull_up_drv_4ma>,
						<1 GPIO_A3 RK_FUNC_GPIO &pcfg_pull_up_drv_4ma>,
						<1 GPIO_A4 RK_FUNC_GPIO &pcfg_pull_up_drv_4ma>;
			};
		};

		sdio1 {
			sdio1_bus1: sdio1-bus1 {
				rockchip,pins = <3 GPIO_A2 RK_FUNC_1 &pcfg_pull_up_drv_4ma>;
			};

			sdio1_bus4: sdio1-bus4 {
				rockchip,pins = <3 GPIO_A2 RK_FUNC_1 &pcfg_pull_up_drv_4ma>,
						<3 GPIO_A3 RK_FUNC_1 &pcfg_pull_up_drv_4ma>,
						<3 GPIO_A4 RK_FUNC_1 &pcfg_pull_up_drv_4ma>,
						<3 GPIO_A5 RK_FUNC_1 &pcfg_pull_up_drv_4ma>;
			};

			sdio1_cmd: sdio1-cmd {
				rockchip,pins = <3 GPIO_A1 RK_FUNC_1 &pcfg_pull_up_drv_4ma>;
			};

			sdio1_clk: sdio1-clk {
				rockchip,pins = <3 GPIO_A0 RK_FUNC_1 &pcfg_pull_none_drv_4ma>;
			};

			sdio1_gpio: sdio1-gpio {
				rockchip,pins = <3 GPIO_A3 RK_FUNC_GPIO &pcfg_pull_up_drv_4ma>,
						<3 GPIO_A0 RK_FUNC_GPIO &pcfg_pull_up_drv_4ma>,
						<3 GPIO_A1 RK_FUNC_GPIO &pcfg_pull_up_drv_4ma>,
						<3 GPIO_A2 RK_FUNC_GPIO &pcfg_pull_up_drv_4ma>,
						<3 GPIO_A3 RK_FUNC_GPIO &pcfg_pull_up_drv_4ma>,
						<3 GPIO_A4 RK_FUNC_GPIO &pcfg_pull_up_drv_4ma>;
			};
		};

		emmc {
			emmc_clk: emmc-clk {
				rockchip,pins = <2 GPIO_A7 RK_FUNC_2 &pcfg_pull_none_drv_8ma>;
			};

			emmc_cmd: emmc-cmd {
				rockchip,pins = <1 GPIO_C6 RK_FUNC_2 &pcfg_pull_up_drv_8ma>;
			};

			emmc_pwren: emmc-pwren {
				rockchip,pins = <2 GPIO_A5 RK_FUNC_2 &pcfg_pull_none>;
			};

			emmc_rstnout: emmc_rstnout {
				rockchip,pins = <1 GPIO_C7 RK_FUNC_2 &pcfg_pull_none>;
			};

			emmc_bus1: emmc-bus1 {
				rockchip,pins = <1 GPIO_D0 RK_FUNC_2 &pcfg_pull_up_drv_8ma>;
			};

			emmc_bus4: emmc-bus4 {
				rockchip,pins = <1 GPIO_D0 RK_FUNC_2 &pcfg_pull_up_drv_8ma>,
						<1 GPIO_D1 RK_FUNC_2 &pcfg_pull_up_drv_8ma>,
						<1 GPIO_D2 RK_FUNC_2 &pcfg_pull_up_drv_8ma>,
						<1 GPIO_D3 RK_FUNC_2 &pcfg_pull_up_drv_8ma>;
			};

			emmc_bus8: emmc-bus8 {
				rockchip,pins = <1 GPIO_D0 RK_FUNC_2 &pcfg_pull_up_drv_8ma>,
						<1 GPIO_D1 RK_FUNC_2 &pcfg_pull_up_drv_8ma>,
						<1 GPIO_D2 RK_FUNC_2 &pcfg_pull_up_drv_8ma>,
						<1 GPIO_D3 RK_FUNC_2 &pcfg_pull_up_drv_8ma>,
						<1 GPIO_D4 RK_FUNC_2 &pcfg_pull_up_drv_8ma>,
						<1 GPIO_D5 RK_FUNC_2 &pcfg_pull_up_drv_8ma>,
						<1 GPIO_D6 RK_FUNC_2 &pcfg_pull_up_drv_8ma>,
						<1 GPIO_D7 RK_FUNC_2 &pcfg_pull_up_drv_8ma>;
			};
		};

		emmc1 {
			emmc1_clk: emmc1-clk {
				rockchip,pins = <2 GPIO_A7 RK_FUNC_2 &pcfg_pull_none_drv_8ma>;
			};

			emmc1_cmd: emmc1-cmd {
				rockchip,pins = <2 GPIO_A4 RK_FUNC_2 &pcfg_pull_up_drv_8ma>;
			};

			emmc1_pwren: emmc1-pwren {
				rockchip,pins = <2 GPIO_A5 RK_FUNC_2 &pcfg_pull_none>;
			};

			emmc1_rstnout: emmc1_rstnout {
				rockchip,pins = <1 GPIO_C7 RK_FUNC_2 &pcfg_pull_none>;
			};

			emmc1_bus1: emmc1-bus1 {
				rockchip,pins = <1 GPIO_D0 RK_FUNC_2 &pcfg_pull_up_drv_8ma>;
			};

			emmc1_bus4: emmc1-bus4 {
				rockchip,pins = <1 GPIO_D0 RK_FUNC_2 &pcfg_pull_up_drv_8ma>,
						<1 GPIO_D1 RK_FUNC_2 &pcfg_pull_up_drv_8ma>,
						<1 GPIO_D2 RK_FUNC_2 &pcfg_pull_up_drv_8ma>,
						<1 GPIO_D3 RK_FUNC_2 &pcfg_pull_up_drv_8ma>;
			};

			emmc1_bus8: emmc1-bus8 {
				rockchip,pins = <1 GPIO_D0 RK_FUNC_2 &pcfg_pull_up_drv_8ma>,
						<1 GPIO_D1 RK_FUNC_2 &pcfg_pull_up_drv_8ma>,
						<1 GPIO_D2 RK_FUNC_2 &pcfg_pull_up_drv_8ma>,
						<1 GPIO_D3 RK_FUNC_2 &pcfg_pull_up_drv_8ma>,
						<1 GPIO_D4 RK_FUNC_2 &pcfg_pull_up_drv_8ma>,
						<1 GPIO_D5 RK_FUNC_2 &pcfg_pull_up_drv_8ma>,
						<1 GPIO_D6 RK_FUNC_2 &pcfg_pull_up_drv_8ma>,
						<1 GPIO_D7 RK_FUNC_2 &pcfg_pull_up_drv_8ma>;
			};
		};

		pwm0 {
			pwm0_pin: pwm0-pin {
				rockchip,pins = <0 GPIO_D2 RK_FUNC_1 &pcfg_pull_none>;
			};
		};

		pwm01 {
			pwm01_pin: pwm01-pin {
				rockchip,pins = <3 GPIO_C5 RK_FUNC_1 &pcfg_pull_none>;
			};
		};

		pwm1 {
			pwm1_pin: pwm1-pin {
				rockchip,pins = <0 GPIO_D3 RK_FUNC_1 &pcfg_pull_none>;
			};
		};

		pwm11 {
			pwm11_pin: pwm11-pin {
				rockchip,pins = <0 GPIO_D6 RK_FUNC_2 &pcfg_pull_none>;
			};
		};

		pwm2 {
			pwm2_pin: pwm2-pin {
				rockchip,pins = <0 GPIO_D4 RK_FUNC_1 &pcfg_pull_none>;
			};
		};

		pwm21 {
			pwm21_pin: pwm21-pin {
				rockchip,pins = <1 GPIO_B4 RK_FUNC_2 &pcfg_pull_none>;
			};
		};

		pwmir {
			pwmir_pin: pwmir-pin {
				rockchip,pins = <3 GPIO_D2 RK_FUNC_1 &pcfg_pull_none>;
			};
		};

		pwmir1 {
			pwmir1_pin: pwmir1-pin {
				rockchip,pins = <1 GPIO_B3 RK_FUNC_2 &pcfg_pull_none>;
			};
		};

		gmac {
			rgmii_pins: rgmii-pins {
				rockchip,pins =	<2 GPIO_B6 RK_FUNC_1 &pcfg_pull_none>,
						<2 GPIO_B4 RK_FUNC_1 &pcfg_pull_none>,
						<2 GPIO_D1 RK_FUNC_1 &pcfg_pull_none>,
						<2 GPIO_C3 RK_FUNC_1 &pcfg_pull_none_drv_12ma>,
						<2 GPIO_C2 RK_FUNC_1 &pcfg_pull_none_drv_12ma>,
						<2 GPIO_C6 RK_FUNC_1 &pcfg_pull_none_drv_12ma>,
						<2 GPIO_C7 RK_FUNC_1 &pcfg_pull_none_drv_12ma>,
						<2 GPIO_B1 RK_FUNC_1 &pcfg_pull_none_drv_12ma>,
						<2 GPIO_B5 RK_FUNC_1 &pcfg_pull_none_drv_12ma>,
						<2 GPIO_C1 RK_FUNC_1 &pcfg_pull_none>,
						<2 GPIO_C0 RK_FUNC_1 &pcfg_pull_none>,
						<2 GPIO_C5 RK_FUNC_2 &pcfg_pull_none>,
						<2 GPIO_C4 RK_FUNC_2 &pcfg_pull_none>,
						<2 GPIO_B3 RK_FUNC_1 &pcfg_pull_none>,
						<2 GPIO_B0 RK_FUNC_1 &pcfg_pull_none>;
			};

			rmii_pins: rmii-pins {
				rockchip,pins =	<2 GPIO_B6 RK_FUNC_1 &pcfg_pull_none>,
						<2 GPIO_B4 RK_FUNC_1 &pcfg_pull_none>,
						<2 GPIO_D1 RK_FUNC_1 &pcfg_pull_none>,
						<2 GPIO_C3 RK_FUNC_1 &pcfg_pull_none_drv_12ma>,
						<2 GPIO_C2 RK_FUNC_1 &pcfg_pull_none_drv_12ma>,
						<2 GPIO_B5 RK_FUNC_1 &pcfg_pull_none_drv_12ma>,
						<2 GPIO_C1 RK_FUNC_1 &pcfg_pull_none>,
						<2 GPIO_C0 RK_FUNC_1 &pcfg_pull_none>,
						<2 GPIO_B0 RK_FUNC_1 &pcfg_pull_none>,
						<2 GPIO_B7 RK_FUNC_1 &pcfg_pull_none>;
			};

			phy_pins: phy-pins {
				rockchip,pins =	<2 GPIO_B6 RK_FUNC_2 &pcfg_pull_none>,
						<2 GPIO_B0 RK_FUNC_2 &pcfg_pull_none>;
			};
		};

		tsadc_pin {
			tsadc_int: tsadc-int {
				rockchip,pins =	<0 GPIO_D0 RK_FUNC_2 &pcfg_pull_none>;
			};
			tsadc_gpio: tsadc-gpio {
				rockchip,pins =	<0 GPIO_D0 RK_FUNC_GPIO &pcfg_pull_none>;
			};
		};

		hdmi_pin {
			hdmi_cec: hdmi-cec {
				rockchip,pins =	<0 GPIO_C4 RK_FUNC_1 &pcfg_pull_none>;
			};

			hdmi_hpd: hdmi-hpd {
				rockchip,pins =	<0 GPIO_B7 RK_FUNC_1 &pcfg_pull_down>;
			};
		};

		hdmi_i2c {
			hdmii2c_xfer: hdmii2c-xfer {
				rockchip,pins = <0 GPIO_A6 RK_FUNC_2 &pcfg_pull_none>,
						<0 GPIO_A7 RK_FUNC_2 &pcfg_pull_none>;
			};
		};
	};
};
